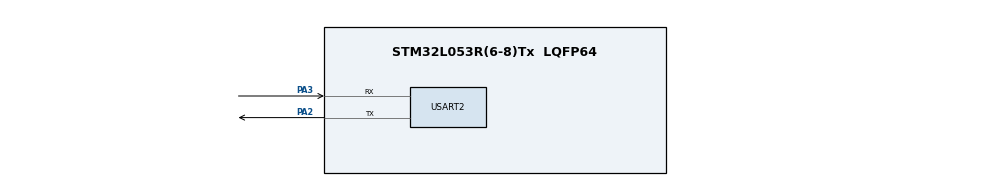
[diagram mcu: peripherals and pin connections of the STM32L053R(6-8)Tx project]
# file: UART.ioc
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Mcu.Family=STM32L0
Mcu.Name=STM32L053R(6-8)Tx
Mcu.Package=LQFP64
NVIC.USART2_IRQn=true\:0\:0\:false\:false\:true\:true\:true
PA2.Mode=Asynchronous
PA2.Signal=USART2_TX
PA3.Mode=Asynchronous
PA3.Signal=USART2_RX
ProjectManager.HeapSize=0x200
ProjectManager.StackSize=0x400
ProjectManager.TargetToolchain=STM32CubeIDE
RCC.AHBFreq_Value=32000000
RCC.APB1Freq_Value=32000000
RCC.APB1TimFreq_Value=32000000
RCC.APB2Freq_Value=32000000
RCC.APB2TimFreq_Value=32000000
RCC.HCLKFreq_Value=32000000
RCC.HSE_VALUE=8000000
RCC.HSI16_VALUE=16000000
RCC.HSI48_VALUE=48000000
RCC.HSI_VALUE=16000000
RCC.LSEState=RCC_LSE_ON
RCC.LSE_VALUE=32768
RCC.MSI_VALUE=2097000
RCC.PLLMUL=RCC_PLLMUL_4
RCC.SYSCLKFreq_VALUE=32000000
RCC.SYSCLKSource=RCC_SYSCLKSOURCE_PLLCLK
RCC.VCOOutputFreq_Value=64000000
USART2.VirtualMode-Asynchronous=VM_ASYNC
board=NUCLEO-L053R8

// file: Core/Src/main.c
/* USER CODE BEGIN Header */
/**
  ******************************************************************************
  * @file           : main.c
  * @brief          : Main program body
  ******************************************************************************
  * @attention
  *
  * <h2><center>&copy; Copyright (c) 2020 STMicroelectronics.
  * All rights reserved.</center></h2>
  *
  * This software component is licensed by ST under BSD 3-Clause license,
  * the "License"; You may not use this file except in compliance with the
  * License. You may obtain a copy of the License at:
  *                        opensource.org/licenses/BSD-3-Clause
  *
  ******************************************************************************
  */
/* USER CODE END Header */

#include "main.h"

/* USER CODE BEGIN Includes */
#include "stdio.h"
/* USER CODE END Includes */

/* USER CODE BEGIN PV */

//create buffer to hold data and a counter
#if 0 //For not using printf part
uint8_t text[12] = "hello world\n";
uint8_t num_of_byte = 0;
#endif
/* USER CODE END PV */

void SystemClock_Config(void);
static void MX_GPIO_Init(void);
static void MX_USART2_UART_Init(void);

int main(void)
{

  /* MCU Configuration--------------------------------------------------------*/

  /* Reset of all peripherals, Initializes the Flash interface and the Systick. */

  LL_APB2_GRP1_EnableClock(LL_APB2_GRP1_PERIPH_SYSCFG);
  LL_APB1_GRP1_EnableClock(LL_APB1_GRP1_PERIPH_PWR);

  /* System interrupt init*/

  /* Configure the system clock */
  SystemClock_Config();

  /* Initialize all configured peripherals */
  MX_GPIO_Init();
  MX_USART2_UART_Init();
  /* USER CODE BEGIN 2 */
  LL_USART_EnableIT_RXNE(USART2);
  /* USER CODE END 2 */

  /* Infinite loop */
  /* USER CODE BEGIN WHILE */
  while (1)
  {
#if 0 //For not using printf part
	  while(num_of_byte <= (sizeof(text) - 1))
	  {
		  //waiting until the Transmit Empty flag is set
		  while(!LL_USART_IsActiveFlag_TXE(USART2));

		  //send data byte by byte
		  LL_USART_TransmitData8(USART2, text[num_of_byte++]);
	  }

	  //reset the counter
	  num_of_byte = 0;

	  //Wait until the transmit complete Flag to be raised
	  while (!LL_USART_IsActiveFlag_TC(USART2));
#endif

#if 0 //For using printf part
	  printf("hello world\n");
	  LL_mDelay(2000);
#endif
    /* USER CODE END WHILE */

  }
}

void SystemClock_Config(void)
{
  LL_FLASH_SetLatency(LL_FLASH_LATENCY_1);

  if(LL_FLASH_GetLatency() != LL_FLASH_LATENCY_1)
  {
  Error_Handler();
  }
  LL_PWR_SetRegulVoltageScaling(LL_PWR_REGU_VOLTAGE_SCALE1);
  LL_RCC_HSI_Enable();

   /* Wait till HSI is ready */
  while(LL_RCC_HSI_IsReady() != 1)
  {

  }
  LL_RCC_HSI_SetCalibTrimming(16);
  LL_RCC_PLL_ConfigDomain_SYS(LL_RCC_PLLSOURCE_HSI, LL_RCC_PLL_MUL_4, LL_RCC_PLL_DIV_2);
  LL_RCC_PLL_Enable();

   /* Wait till PLL is ready */
  while(LL_RCC_PLL_IsReady() != 1)
  {

  }
  LL_RCC_SetAHBPrescaler(LL_RCC_SYSCLK_DIV_1);
  LL_RCC_SetAPB1Prescaler(LL_RCC_APB1_DIV_1);
  LL_RCC_SetAPB2Prescaler(LL_RCC_APB2_DIV_1);
  LL_RCC_SetSysClkSource(LL_RCC_SYS_CLKSOURCE_PLL);

   /* Wait till System clock is ready */
  while(LL_RCC_GetSysClkSource() != LL_RCC_SYS_CLKSOURCE_STATUS_PLL)
  {

  }

  LL_Init1msTick(32000000);

  LL_SetSystemCoreClock(32000000);
  LL_RCC_SetUSARTClockSource(LL_RCC_USART2_CLKSOURCE_PCLK1);
}

static void MX_USART2_UART_Init(void)
{

  LL_USART_InitTypeDef USART_InitStruct = {0};

  LL_GPIO_InitTypeDef GPIO_InitStruct = {0};

  /* Peripheral clock enable */
  LL_APB1_GRP1_EnableClock(LL_APB1_GRP1_PERIPH_USART2);

  LL_IOP_GRP1_EnableClock(LL_IOP_GRP1_PERIPH_GPIOA);
  /**USART2 GPIO Configuration
  PA2   ------> USART2_TX
  PA3   ------> USART2_RX
  */
  GPIO_InitStruct.Pin = LL_GPIO_PIN_2;
  GPIO_InitStruct.Mode = LL_GPIO_MODE_ALTERNATE;
  GPIO_InitStruct.Speed = LL_GPIO_SPEED_FREQ_VERY_HIGH;
  GPIO_InitStruct.OutputType = LL_GPIO_OUTPUT_PUSHPULL;
  GPIO_InitStruct.Pull = LL_GPIO_PULL_NO;
  GPIO_InitStruct.Alternate = LL_GPIO_AF_4;
  LL_GPIO_Init(GPIOA, &GPIO_InitStruct);

  GPIO_InitStruct.Pin = LL_GPIO_PIN_3;
  GPIO_InitStruct.Mode = LL_GPIO_MODE_ALTERNATE;
  GPIO_InitStruct.Speed = LL_GPIO_SPEED_FREQ_VERY_HIGH;
  GPIO_InitStruct.OutputType = LL_GPIO_OUTPUT_PUSHPULL;
  GPIO_InitStruct.Pull = LL_GPIO_PULL_NO;
  GPIO_InitStruct.Alternate = LL_GPIO_AF_4;
  LL_GPIO_Init(GPIOA, &GPIO_InitStruct);

  /* USART2 interrupt Init */
  NVIC_SetPriority(USART2_IRQn, 0);
  NVIC_EnableIRQ(USART2_IRQn);

  USART_InitStruct.BaudRate = 115200;
  USART_InitStruct.DataWidth = LL_USART_DATAWIDTH_8B;
  USART_InitStruct.StopBits = LL_USART_STOPBITS_1;
  USART_InitStruct.Parity = LL_USART_PARITY_NONE;
  USART_InitStruct.TransferDirection = LL_USART_DIRECTION_TX_RX;
  USART_InitStruct.HardwareFlowControl = LL_USART_HWCONTROL_NONE;
  USART_InitStruct.OverSampling = LL_USART_OVERSAMPLING_16;
  LL_USART_Init(USART2, &USART_InitStruct);
  LL_USART_ConfigAsyncMode(USART2);
  LL_USART_Enable(USART2);

}

static void MX_GPIO_Init(void)
{

  /* GPIO Ports Clock Enable */
  LL_IOP_GRP1_EnableClock(LL_IOP_GRP1_PERIPH_GPIOA);

}

/* USER CODE BEGIN 4 */
int _write(int file, uint8_t *buf, int nbytes)
{
	uint8_t num_of_byte = 0;
	while(num_of_byte <= nbytes - 1)
	{
		//waiting until the Transmit Empty flag is set
		while(!LL_USART_IsActiveFlag_TXE(USART2));

		//send data byte by byte
		LL_USART_TransmitData8(USART2, buf[num_of_byte++]);
	}

	//Wait until the transmit complete Flag to be raised
	while (!LL_USART_IsActiveFlag_TC(USART2));
    return nbytes;
}

void ByteReceivedCallback(void)
{
	uint8_t ch;
	// read the data from the data reception register, by doing this, we also clear the interrupt flag
	ch = LL_USART_ReceiveData8(USART2);

	//waiting until the Transmit Empty flag is set
	while(!LL_USART_IsActiveFlag_TXE(USART2));

	LL_USART_TransmitData8(USART2, ch);

	//Wait until the transmit complete Flag to be raised
	while (!LL_USART_IsActiveFlag_TC(USART2));
}
/* USER CODE END 4 */

void Error_Handler(void)
{
}

/************************ (C) COPYRIGHT STMicroelectronics *****END OF FILE****/
